VERSION "1.0"

NS_ :

BS_:

BU_: ECM ECU TINYML_ECU

BO_ 257 VehicleSpeed: 8 ECU
 SG_ SpeedKmh : 0|16@1+ (0.1,0) [0|6553.5] "km/h" ECM

BO_ 258 EngineTemp: 8 ECU
 SG_ EngTemp : 0|8@1+ (1,-40) [-40|215] "degC" ECM

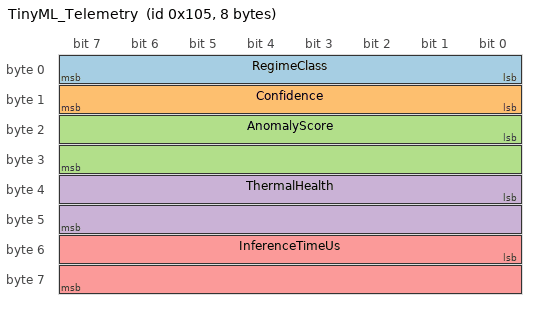
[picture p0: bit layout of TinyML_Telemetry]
BO_ 261 TinyML_Telemetry: 8 TINYML_ECU
 SG_ RegimeClass : 0|8@1+ (1,0) [0|4] "class" ECM
 SG_ Confidence : 8|8@1+ (1,0) [0|100] "%" ECM
 SG_ AnomalyScore : 16|16@1+ (0.1,0) [0|100] "%" ECM
 SG_ ThermalHealth : 32|16@1+ (0.1,0) [0|100] "%" ECM
 SG_ InferenceTimeUs : 48|16@1+ (1,0) [0|65535] "us" ECM

CM_ "Standard 11-bit CAN communication matrix for the TorqueBus Studio virtual vehicle example (examples/projects/virtual-vehicle.tbsproj, ecu_vehicle.lua, and ecu_vehicle_dbc.lua).";
CM_ BU_ ECM "Engine Control Module / Instrument Cluster consumer receiving vehicle dynamics and TinyML inference telemetry.";
CM_ BU_ ECU "Simulated Vehicle ECU (ecu_vehicle.lua / ecu_vehicle_dbc.lua) transmitting vehicle speed (0x101) and engine coolant temperature (0x102).";
CM_ BU_ TINYML_ECU "TinyML On-Edge Virtual ECU consuming vehicle speed and temperature to emit real-time neural inference telemetry (0x105).";

CM_ BO_ 257 "CAN ID 0x101 (257) - VehicleSpeed. Transmitted by ECU every 100 ms (10 Hz). Carries 16-bit Intel vehicle road speed in km/h.";
CM_ BO_ 258 "CAN ID 0x102 (258) - EngineTemp. Transmitted by ECU every 1000 ms (1 Hz). Carries 8-bit engine coolant temperature with -40 degC offset.";
CM_ BO_ 261 "CAN ID 0x105 (261) - TinyML_Telemetry. Emitted by TINYML_ECU every 100 ms on each inference pass. Carries operating regime classification, confidence, anomaly score, thermal health, and inference latency.";

CM_ SG_ 257 SpeedKmh "Vehicle road speed (uint16 little-endian, 0.1 km/h per bit, offset 0, range 0 to 6553.5 km/h; e.g. 85.0 km/h = raw 850 = 0x0352 -> bytes 52 03).";
CM_ SG_ 258 EngTemp "Engine coolant temperature (uint8, 1 degC per bit, offset -40 degC, range -40 to 215 degC; e.g. 70 degC = raw 110 = 0x6E).";
CM_ SG_ 261 RegimeClass "Predicted operating regime class from the on-edge neural network (0=Idle, 1=Cruise, 2=HighLoad, 3=ThermalStress, 4=Anomaly).";
CM_ SG_ 261 Confidence "Softmax classification confidence for the active operating regime (1 %/bit, range 0 to 100 %).";
CM_ SG_ 261 AnomalyScore "Multivariate anomaly score computed by the TinyML model (uint16 little-endian, 0.1 %/bit, range 0 to 100 %).";
CM_ SG_ 261 ThermalHealth "Estimated engine thermal health margin (uint16 little-endian, 0.1 %/bit, range 0 to 100 %).";
CM_ SG_ 261 InferenceTimeUs "Deterministic neural network forward-pass execution latency in microseconds (uint16 little-endian, 1 us/bit, range 0 to 65535 us).";

BA_DEF_  "BusType" STRING ;
BA_DEF_  "DBName" STRING ;
BA_DEF_ BO_  "GenMsgCycleTime" INT 0 3600000;
BA_DEF_ BO_  "VFrameFormat" ENUM  "StandardCAN","ExtendedCAN","reserved","J1939PG","reserved","reserved","reserved","reserved","reserved","reserved","reserved","reserved","reserved","reserved","StandardCAN_FD","ExtendedCAN_FD";
BA_DEF_DEF_  "BusType" "CAN";
BA_DEF_DEF_  "DBName" "";
BA_DEF_DEF_  "GenMsgCycleTime" 0;
BA_DEF_DEF_  "VFrameFormat" "StandardCAN";
BA_ "DBName" "vehicle";
BA_ "GenMsgCycleTime" BO_ 257 100;
BA_ "GenMsgCycleTime" BO_ 258 1000;
BA_ "GenMsgCycleTime" BO_ 261 100;

VAL_ 261 RegimeClass 0 "Idle" 1 "Cruise" 2 "HighLoad" 3 "ThermalStress" 4 "Anomaly" ;
